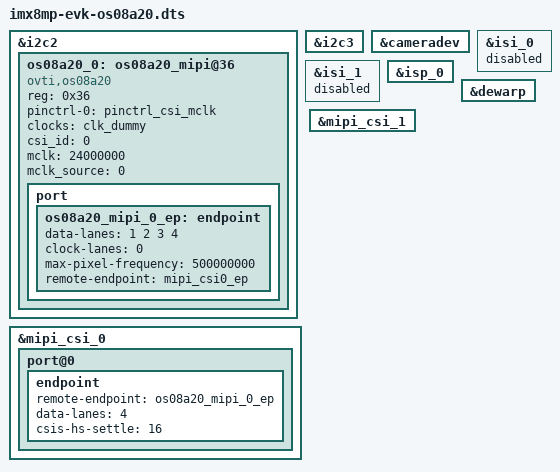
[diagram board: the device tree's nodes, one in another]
// SPDX-License-Identifier: (GPL-2.0+ OR MIT)
/*
 * Copyright 2022 NXP
 *
 * This program is free software; you can redistribute it and/or
 * modify it under the terms of the GNU General Public License
 * as published by the Free Software Foundation; either version 2
 * of the License, or (at your option) any later version.
 *
 * This program is distributed in the hope that it will be useful,
 * but WITHOUT ANY WARRANTY; without even the implied warranty of
 * MERCHANTABILITY or FITNESS FOR A PARTICULAR PURPOSE.  See the
 * GNU General Public License for more details.
 */

/dts-v1/;

#include "imx8mp-evk.dts"

&i2c2 {
	/delete-node/ov5640_mipi@3c;

	os08a20_0: os08a20_mipi@36 {
		compatible = "ovti,os08a20";
		reg = <0x36>;
		pinctrl-names = "default";
		pinctrl-0 = <&pinctrl_csi_mclk>;
		clocks = <&clk_dummy>;
		clock-names = "csi_mclk";
		csi_id = <0>;
		mclk = <24000000>;
		mclk_source = <0>;
		status = "okay";

		port {
			os08a20_mipi_0_ep: endpoint {
				data-lanes = <1 2 3 4>;
				clock-lanes = <0>;
				max-pixel-frequency = /bits/ 64 <500000000>;
				remote-endpoint = <&mipi_csi0_ep>;
			};
		};

	};
};

&i2c3 {
	/delete-node/ov5640_mipi@3c;

};

&cameradev {
	status = "okay";
};

&isi_0 {
	status = "disabled";
};

&isi_1 {
	status = "disabled";
};

&isp_0 {
	status = "okay";
};

&dewarp {
	status = "okay";
};

&mipi_csi_0 {
	status = "okay";

	port@0 {
		endpoint {
			remote-endpoint = <&os08a20_mipi_0_ep>;
			data-lanes = <4>;
			csis-hs-settle = <16>;
		};
	};
};

&mipi_csi_1 {
	/delete-node/port@1;
};
